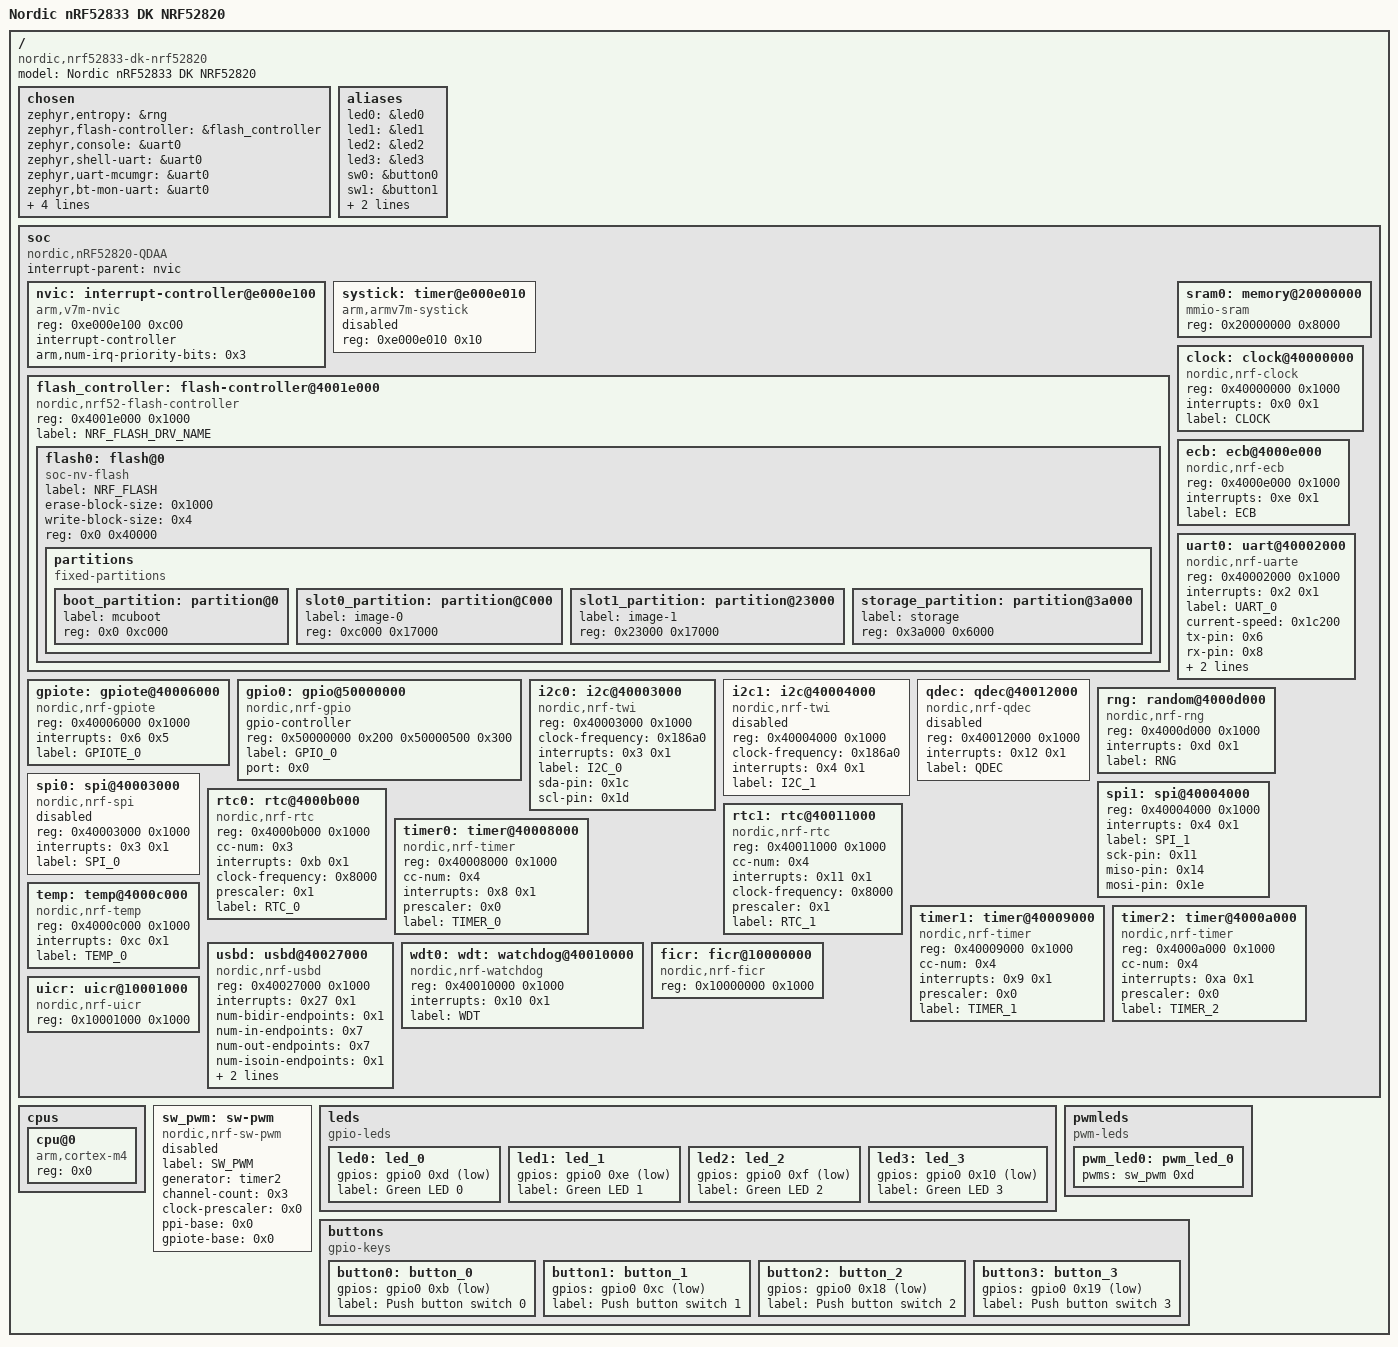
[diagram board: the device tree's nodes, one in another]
/dts-v1/;

/ {
	#address-cells = < 0x1 >;
	#size-cells = < 0x1 >;
	model = "Nordic nRF52833 DK NRF52820";
	compatible = "nordic,nrf52833-dk-nrf52820";
	chosen {
		zephyr,entropy = &rng;
		zephyr,flash-controller = &flash_controller;
		zephyr,console = &uart0;
		zephyr,shell-uart = &uart0;
		zephyr,uart-mcumgr = &uart0;
		zephyr,bt-mon-uart = &uart0;
		zephyr,bt-c2h-uart = &uart0;
		zephyr,sram = &sram0;
		zephyr,flash = &flash0;
		zephyr,code-partition = &slot0_partition;
	};
	aliases {
		led0 = &led0;
		led1 = &led1;
		led2 = &led2;
		led3 = &led3;
		sw0 = &button0;
		sw1 = &button1;
		sw2 = &button2;
		sw3 = &button3;
	};
	soc {
		#address-cells = < 0x1 >;
		#size-cells = < 0x1 >;
		compatible = "nordic,nRF52820-QDAA", "nordic,nRF52820", "nordic,nRF52", "simple-bus";
		interrupt-parent = < &nvic >;
		ranges;
		nvic: interrupt-controller@e000e100 {
			compatible = "arm,v7m-nvic";
			reg = < 0xe000e100 0xc00 >;
			interrupt-controller;
			#interrupt-cells = < 0x2 >;
			arm,num-irq-priority-bits = < 0x3 >;
			phandle = < 0x1 >;
		};
		systick: timer@e000e010 {
			compatible = "arm,armv7m-systick";
			reg = < 0xe000e010 0x10 >;
			status = "disabled";
		};
		flash_controller: flash-controller@4001e000 {
			compatible = "nordic,nrf52-flash-controller";
			reg = < 0x4001e000 0x1000 >;
			#address-cells = < 0x1 >;
			#size-cells = < 0x1 >;
			label = "NRF_FLASH_DRV_NAME";
			flash0: flash@0 {
				compatible = "soc-nv-flash";
				label = "NRF_FLASH";
				erase-block-size = < 0x1000 >;
				write-block-size = < 0x4 >;
				reg = < 0x0 0x40000 >;
				partitions {
					compatible = "fixed-partitions";
					#address-cells = < 0x1 >;
					#size-cells = < 0x1 >;
					boot_partition: partition@0 {
						label = "mcuboot";
						reg = < 0x0 0xc000 >;
					};
					slot0_partition: partition@C000 {
						label = "image-0";
						reg = < 0xc000 0x17000 >;
					};
					slot1_partition: partition@23000 {
						label = "image-1";
						reg = < 0x23000 0x17000 >;
					};
					storage_partition: partition@3a000 {
						label = "storage";
						reg = < 0x3a000 0x6000 >;
					};
				};
			};
		};
		sram0: memory@20000000 {
			compatible = "mmio-sram";
			reg = < 0x20000000 0x8000 >;
		};
		clock: clock@40000000 {
			compatible = "nordic,nrf-clock";
			reg = < 0x40000000 0x1000 >;
			interrupts = < 0x0 0x1 >;
			status = "okay";
			label = "CLOCK";
		};
		ecb: ecb@4000e000 {
			compatible = "nordic,nrf-ecb";
			reg = < 0x4000e000 0x1000 >;
			interrupts = < 0xe 0x1 >;
			status = "okay";
			label = "ECB";
		};
		uart0: uart@40002000 {
			reg = < 0x40002000 0x1000 >;
			interrupts = < 0x2 0x1 >;
			status = "okay";
			label = "UART_0";
			compatible = "nordic,nrf-uarte";
			current-speed = < 0x1c200 >;
			tx-pin = < 0x6 >;
			rx-pin = < 0x8 >;
			rts-pin = < 0x5 >;
			cts-pin = < 0x7 >;
		};
		gpiote: gpiote@40006000 {
			compatible = "nordic,nrf-gpiote";
			reg = < 0x40006000 0x1000 >;
			interrupts = < 0x6 0x5 >;
			status = "okay";
			label = "GPIOTE_0";
		};
		gpio0: gpio@50000000 {
			compatible = "nordic,nrf-gpio";
			gpio-controller;
			reg = < 0x50000000 0x200 0x50000500 0x300 >;
			#gpio-cells = < 0x2 >;
			label = "GPIO_0";
			status = "okay";
			port = < 0x0 >;
			phandle = < 0x3 >;
		};
		i2c0: i2c@40003000 {
			#address-cells = < 0x1 >;
			#size-cells = < 0x0 >;
			reg = < 0x40003000 0x1000 >;
			clock-frequency = < 0x186a0 >;
			interrupts = < 0x3 0x1 >;
			status = "okay";
			label = "I2C_0";
			compatible = "nordic,nrf-twi";
			sda-pin = < 0x1c >;
			scl-pin = < 0x1d >;
		};
		i2c1: i2c@40004000 {
			#address-cells = < 0x1 >;
			#size-cells = < 0x0 >;
			reg = < 0x40004000 0x1000 >;
			clock-frequency = < 0x186a0 >;
			interrupts = < 0x4 0x1 >;
			status = "disabled";
			label = "I2C_1";
			compatible = "nordic,nrf-twi";
		};
		qdec: qdec@40012000 {
			compatible = "nordic,nrf-qdec";
			reg = < 0x40012000 0x1000 >;
			interrupts = < 0x12 0x1 >;
			status = "disabled";
			label = "QDEC";
		};
		rng: random@4000d000 {
			compatible = "nordic,nrf-rng";
			reg = < 0x4000d000 0x1000 >;
			interrupts = < 0xd 0x1 >;
			status = "okay";
			label = "RNG";
		};
		spi0: spi@40003000 {
			#address-cells = < 0x1 >;
			#size-cells = < 0x0 >;
			reg = < 0x40003000 0x1000 >;
			interrupts = < 0x3 0x1 >;
			status = "disabled";
			label = "SPI_0";
			compatible = "nordic,nrf-spi";
		};
		spi1: spi@40004000 {
			#address-cells = < 0x1 >;
			#size-cells = < 0x0 >;
			reg = < 0x40004000 0x1000 >;
			interrupts = < 0x4 0x1 >;
			status = "okay";
			label = "SPI_1";
			sck-pin = < 0x11 >;
			miso-pin = < 0x14 >;
			mosi-pin = < 0x1e >;
		};
		rtc0: rtc@4000b000 {
			compatible = "nordic,nrf-rtc";
			reg = < 0x4000b000 0x1000 >;
			cc-num = < 0x3 >;
			interrupts = < 0xb 0x1 >;
			status = "okay";
			clock-frequency = < 0x8000 >;
			prescaler = < 0x1 >;
			label = "RTC_0";
		};
		rtc1: rtc@40011000 {
			compatible = "nordic,nrf-rtc";
			reg = < 0x40011000 0x1000 >;
			cc-num = < 0x4 >;
			interrupts = < 0x11 0x1 >;
			status = "okay";
			clock-frequency = < 0x8000 >;
			prescaler = < 0x1 >;
			label = "RTC_1";
		};
		timer0: timer@40008000 {
			compatible = "nordic,nrf-timer";
			status = "okay";
			reg = < 0x40008000 0x1000 >;
			cc-num = < 0x4 >;
			interrupts = < 0x8 0x1 >;
			prescaler = < 0x0 >;
			label = "TIMER_0";
		};
		timer1: timer@40009000 {
			compatible = "nordic,nrf-timer";
			status = "okay";
			reg = < 0x40009000 0x1000 >;
			cc-num = < 0x4 >;
			interrupts = < 0x9 0x1 >;
			prescaler = < 0x0 >;
			label = "TIMER_1";
		};
		timer2: timer@4000a000 {
			compatible = "nordic,nrf-timer";
			status = "okay";
			reg = < 0x4000a000 0x1000 >;
			cc-num = < 0x4 >;
			interrupts = < 0xa 0x1 >;
			prescaler = < 0x0 >;
			label = "TIMER_2";
			phandle = < 0x2 >;
		};
		temp: temp@4000c000 {
			compatible = "nordic,nrf-temp";
			reg = < 0x4000c000 0x1000 >;
			interrupts = < 0xc 0x1 >;
			status = "okay";
			label = "TEMP_0";
		};
		usbd: usbd@40027000 {
			compatible = "nordic,nrf-usbd";
			reg = < 0x40027000 0x1000 >;
			interrupts = < 0x27 0x1 >;
			num-bidir-endpoints = < 0x1 >;
			num-in-endpoints = < 0x7 >;
			num-out-endpoints = < 0x7 >;
			num-isoin-endpoints = < 0x1 >;
			num-isoout-endpoints = < 0x1 >;
			status = "okay";
			label = "USBD";
		};
		wdt0: wdt: watchdog@40010000 {
			compatible = "nordic,nrf-watchdog";
			reg = < 0x40010000 0x1000 >;
			interrupts = < 0x10 0x1 >;
			status = "okay";
			label = "WDT";
		};
		ficr: ficr@10000000 {
			compatible = "nordic,nrf-ficr";
			reg = < 0x10000000 0x1000 >;
			status = "okay";
		};
		uicr: uicr@10001000 {
			compatible = "nordic,nrf-uicr";
			reg = < 0x10001000 0x1000 >;
			status = "okay";
		};
	};
	cpus {
		#address-cells = < 0x1 >;
		#size-cells = < 0x0 >;
		cpu@0 {
			device_type = "cpu";
			compatible = "arm,cortex-m4";
			reg = < 0x0 >;
		};
	};
	sw_pwm: sw-pwm {
		compatible = "nordic,nrf-sw-pwm";
		status = "disabled";
		label = "SW_PWM";
		generator = < &timer2 >;
		channel-count = < 0x3 >;
		clock-prescaler = < 0x0 >;
		ppi-base = < 0x0 >;
		gpiote-base = < 0x0 >;
		#pwm-cells = < 0x1 >;
		phandle = < 0x4 >;
	};
	leds {
		compatible = "gpio-leds";
		led0: led_0 {
			gpios = < &gpio0 0xd 0x1 >;
			label = "Green LED 0";
		};
		led1: led_1 {
			gpios = < &gpio0 0xe 0x1 >;
			label = "Green LED 1";
		};
		led2: led_2 {
			gpios = < &gpio0 0xf 0x1 >;
			label = "Green LED 2";
		};
		led3: led_3 {
			gpios = < &gpio0 0x10 0x1 >;
			label = "Green LED 3";
		};
	};
	pwmleds {
		compatible = "pwm-leds";
		pwm_led0: pwm_led_0 {
			pwms = < &sw_pwm 0xd >;
		};
	};
	buttons {
		compatible = "gpio-keys";
		button0: button_0 {
			gpios = < &gpio0 0xb 0x11 >;
			label = "Push button switch 0";
		};
		button1: button_1 {
			gpios = < &gpio0 0xc 0x11 >;
			label = "Push button switch 1";
		};
		button2: button_2 {
			gpios = < &gpio0 0x18 0x11 >;
			label = "Push button switch 2";
		};
		button3: button_3 {
			gpios = < &gpio0 0x19 0x11 >;
			label = "Push button switch 3";
		};
	};
};
